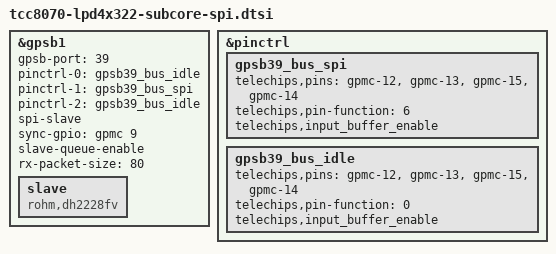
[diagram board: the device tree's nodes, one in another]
/* SPDX-License-Identifier: (GPL-2.0-or-later OR MIT) */
/*
 * Copyright (C) 2023 Telechips Inc.
 */

&gpsb1 {
	status = "okay";
	gpsb-port = <39>;
	pinctrl-names = "idle", "active", "sleep";

	/* IPC-SPI */
	pinctrl-0 = <&gpsb39_bus_idle>;
	pinctrl-1 = <&gpsb39_bus_spi>;
	pinctrl-2 = <&gpsb39_bus_idle>;
	spi-slave;

	/* MICOM_GPIO 1 */
	sync-gpio = <&gpmc 9 0>;
	slave-queue-enable;
	rx-packet-size = <80>;

	#address-cells = <0>;
	#size-cells = <0>;
	slave {
		compatible = "rohm,dh2228fv";
	};

};


&pinctrl {

	gpsb39_bus_spi: gpsb39_bus_spi {
		telechips,pins = "gpmc-12", "gpmc-13", "gpmc-15", "gpmc-14";
		telechips,pin-function = <6>;
		telechips,input_buffer_enable;
	};

	gpsb39_bus_idle: gpsb39_bus_idle {
		telechips,pins = "gpmc-12", "gpmc-13", "gpmc-15", "gpmc-14";
		telechips,pin-function = <0>;
		telechips,input_buffer_enable;
	};
};

